# CY8C4245AXI_483 register map
File version: 0.1
PSoC 4200
Registers are 32-bit, read-write, no defined reset value unless marked. A register's access mark holds for its fields unless they carry their own. Offsets are from the block's base; lines under a group give offsets from that group; [hi:lo] are bit positions; {n}, {i} and the like mark numbered series; 'fields as' and 'values as' point back to an identical list; <NAME> marks a mode.

## Memory map
0x00000000 PWM_1
0x00000000 UART — Serial Communication Block
0x00000000 PWM_2
0x00000000 PWM_3

## PWM_1
Base 0x00000000
0x400F0020 PWM_1_COMPARE_Reg_ 8-bit — UDB.D0 - Assigned Compare Value
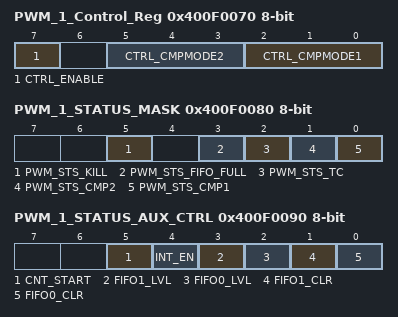
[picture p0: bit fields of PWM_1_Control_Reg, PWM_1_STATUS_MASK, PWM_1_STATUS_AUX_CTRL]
0x400F0070 PWM_1_Control_Reg 8-bit — UDB Control Register - Assigned Control Register Value
  [7] CTRL_ENABLE — Enable the PWM
  [5:3] CTRL_CMPMODE2 — Compare mode 2
  [2:0] CTRL_CMPMODE1 — Compare mode 1
0x400F0080 PWM_1_STATUS_MASK 8-bit — UDB Status bits Interrupt Mask Enable Register
  [5] PWM_STS_KILL ro — Enables the Interrupt on Kill
  [3] PWM_STS_FIFO_FULL ro — FIFO Full Status Mask
  [2] PWM_STS_TC ro — Enables the Interrupt on Terminal Count
  [1] PWM_STS_CMP2 ro — Enables the Interrupt on Compare 2
  [0] PWM_STS_CMP1 ro — Enables the Interrupt on Compare 1
0x400F0090 PWM_1_STATUS_AUX_CTRL 8-bit — UDB Auxilliary Control Register
  [5] CNT_START — FIFO0 clear
    0=E_CNT_START0 (Disable counter); 1=E_CNT_START1 (Enable counter)
  [4] INT_EN
    0=E_INT_EN0 (Interrupt disabled); 1=E_INT_EN1 (Interrupt enabled)
  [3] FIFO1_LVL — FIFO level
    0=E_FIFO_LVL_0 (FIFO LVL: input mode: FIFO not full; output mode: FIFO not empty); 1=E_FIFO_LVL_1 (FIFO LVL: input mode: FIFO at least 1/2 empty; output mode: FIFO at least 1/2 full)
  [2] FIFO0_LVL — FIFO level
    values as FIFO1_LVL
  [1] FIFO1_CLR — FIFO1 clear
    0=E_FIFO_CLR_0 (Normal FIFO operation); 1=E_FIFO_CLR_1 (Clear FIFO state)
  [0] FIFO0_CLR — FIFO0 clear
    values as FIFO1_CLR

## PWM_2
Base 0x00000000
0x400F0023 PWM_2_COMPARE_Reg_ 8-bit — UDB.D0 - Assigned Compare Value
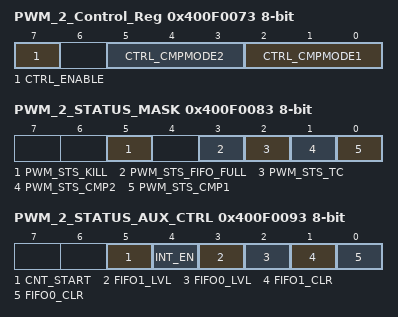
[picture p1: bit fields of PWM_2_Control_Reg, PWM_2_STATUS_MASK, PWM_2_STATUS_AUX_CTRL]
0x400F0073 PWM_2_Control_Reg 8-bit — UDB Control Register - Assigned Control Register Value
  [7] CTRL_ENABLE — Enable the PWM
  [5:3] CTRL_CMPMODE2 — Compare mode 2
  [2:0] CTRL_CMPMODE1 — Compare mode 1
0x400F0083 PWM_2_STATUS_MASK 8-bit — UDB Status bits Interrupt Mask Enable Register
  [5] PWM_STS_KILL ro — Enables the Interrupt on Kill
  [3] PWM_STS_FIFO_FULL ro — FIFO Full Status Mask
  [2] PWM_STS_TC ro — Enables the Interrupt on Terminal Count
  [1] PWM_STS_CMP2 ro — Enables the Interrupt on Compare 2
  [0] PWM_STS_CMP1 ro — Enables the Interrupt on Compare 1
0x400F0093 PWM_2_STATUS_AUX_CTRL 8-bit — UDB Auxilliary Control Register
  [5] CNT_START — FIFO0 clear
    0=E_CNT_START0 (Disable counter); 1=E_CNT_START1 (Enable counter)
  [4] INT_EN
    0=E_INT_EN0 (Interrupt disabled); 1=E_INT_EN1 (Interrupt enabled)
  [3] FIFO1_LVL — FIFO level
    0=E_FIFO_LVL_0 (FIFO LVL: input mode: FIFO not full; output mode: FIFO not empty); 1=E_FIFO_LVL_1 (FIFO LVL: input mode: FIFO at least 1/2 empty; output mode: FIFO at least 1/2 full)
  [2] FIFO0_LVL — FIFO level
    values as FIFO1_LVL
  [1] FIFO1_CLR — FIFO1 clear
    0=E_FIFO_CLR_0 (Normal FIFO operation); 1=E_FIFO_CLR_1 (Clear FIFO state)
  [0] FIFO0_CLR — FIFO0 clear
    values as FIFO1_CLR

## PWM_3
Base 0x00000000
0x400F0022 PWM_3_COMPARE_Reg_ 8-bit — UDB.D0 - Assigned Compare Value
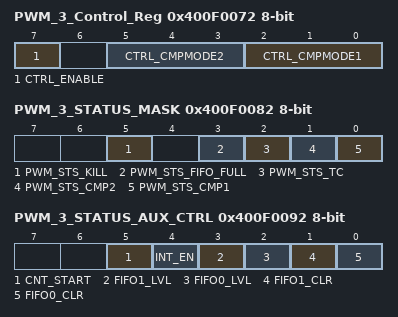
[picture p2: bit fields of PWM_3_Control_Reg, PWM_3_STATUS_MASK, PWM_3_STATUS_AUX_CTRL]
0x400F0072 PWM_3_Control_Reg 8-bit — UDB Control Register - Assigned Control Register Value
  [7] CTRL_ENABLE — Enable the PWM
  [5:3] CTRL_CMPMODE2 — Compare mode 2
  [2:0] CTRL_CMPMODE1 — Compare mode 1
0x400F0082 PWM_3_STATUS_MASK 8-bit — UDB Status bits Interrupt Mask Enable Register
  [5] PWM_STS_KILL ro — Enables the Interrupt on Kill
  [3] PWM_STS_FIFO_FULL ro — FIFO Full Status Mask
  [2] PWM_STS_TC ro — Enables the Interrupt on Terminal Count
  [1] PWM_STS_CMP2 ro — Enables the Interrupt on Compare 2
  [0] PWM_STS_CMP1 ro — Enables the Interrupt on Compare 1
0x400F0092 PWM_3_STATUS_AUX_CTRL 8-bit — UDB Auxilliary Control Register
  [5] CNT_START — FIFO0 clear
    0=E_CNT_START0 (Disable counter); 1=E_CNT_START1 (Enable counter)
  [4] INT_EN
    0=E_INT_EN0 (Interrupt disabled); 1=E_INT_EN1 (Interrupt enabled)
  [3] FIFO1_LVL — FIFO level
    0=E_FIFO_LVL_0 (FIFO LVL: input mode: FIFO not full; output mode: FIFO not empty); 1=E_FIFO_LVL_1 (FIFO LVL: input mode: FIFO at least 1/2 empty; output mode: FIFO at least 1/2 full)
  [2] FIFO0_LVL — FIFO level
    values as FIFO1_LVL
  [1] FIFO1_CLR — FIFO1 clear
    0=E_FIFO_CLR_0 (Normal FIFO operation); 1=E_FIFO_CLR_1 (Clear FIFO state)
  [0] FIFO0_CLR — FIFO0 clear
    values as FIFO1_CLR
